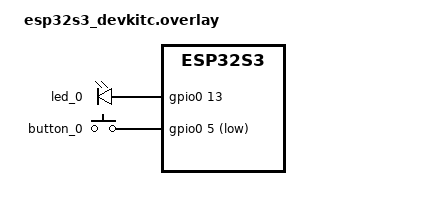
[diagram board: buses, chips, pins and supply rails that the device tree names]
/ {
    aliases {
        my-led = &led_0;
        my-button = &button_0;
    };

    leds {
        compatible = "gpio-leds";
        led_0: d13 {
            gpios = <&gpio0 13 GPIO_ACTIVE_HIGH>;
        };
    };

    buttons {
        compatible = "gpio-keys";
        debounce-interval-ms = <50>;
        polling-mode;

        button_0: d5 {
            gpios = <&gpio0 5 (GPIO_ACTIVE_LOW | GPIO_PULL_UP)>;

        };
    };
};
